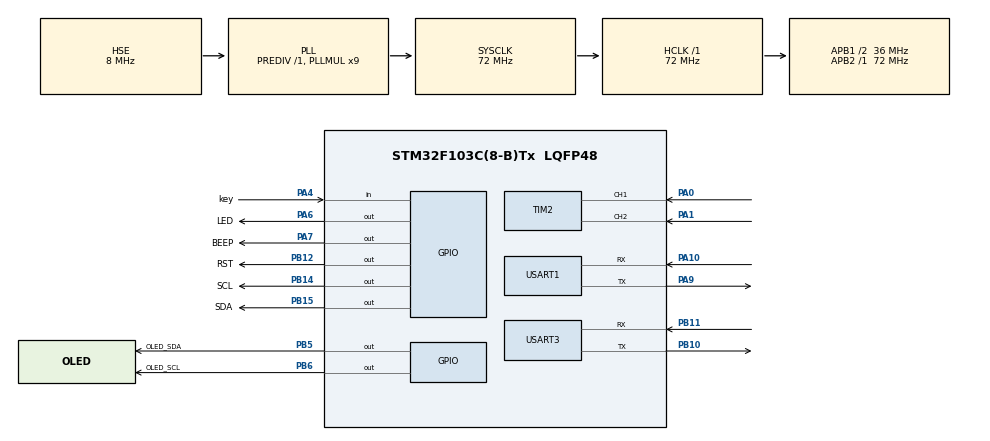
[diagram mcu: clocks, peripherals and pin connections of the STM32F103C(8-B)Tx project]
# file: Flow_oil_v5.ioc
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FREERTOS.HEAP_NUMBER=4
FREERTOS.INCLUDE_uxTaskGetStackHighWaterMark=1
FREERTOS.INCLUDE_vTaskDelay=1
FREERTOS.MEMORY_ALLOCATION=0
FREERTOS.Queues01=SendQueue,4,float,0,Dynamic,NULL,NULL;UploadQueue,1,OilDataWithTime,0,Dynamic,NULL,NULL;RequestQueue,1,uint8_t,0,Dynamic,NULL,NULL;DeleteQueue,1,uint8_t,0,Dynamic,NULL,NULL
FREERTOS.Tasks01=defaultTask,-3,64,StartDefaultTask,As weak,NULL,Dynamic,NULL,NULL;UploadDataTask,1,256,UploadData_Task,As weak,NULL,Dynamic,NULL,NULL;ProcesDataTask,0,256,ProcesData_Task,As weak,NULL,Dynamic,NULL,NULL;StorageDataTask,2,256,StorageData_Task,As weak,NULL,Dynamic,NULL,NULL;oledTask,-1,256,oled_Task,As weak,NULL,Dynamic,NULL,NULL
FREERTOS.configMINIMAL_STACK_SIZE=64
FREERTOS.configTOTAL_HEAP_SIZE=9216
IWDG.Prescaler=IWDG_PRESCALER_256
Mcu.Family=STM32F1
Mcu.Name=STM32F103C(8-B)Tx
Mcu.Package=LQFP48
NVIC.PriorityGroup=NVIC_PRIORITYGROUP_4
NVIC.TIM1_UP_IRQn=true\:15\:0\:false\:false\:true\:false\:false\:true\:true
NVIC.TimeBase=TIM1_UP_IRQn
NVIC.TimeBaseIP=TIM1
NVIC.USART3_IRQn=true\:7\:0\:true\:false\:true\:true\:true\:true\:true
PA0-WKUP.GPIO_PuPd=GPIO_PULLUP
PA0-WKUP.Signal=S_TIM2_CH1_ETR
PA1.GPIO_PuPd=GPIO_PULLUP
PA1.Signal=S_TIM2_CH2
PA10.Mode=Asynchronous
PA10.Signal=USART1_RX
PA13.Mode=Serial_Wire
PA13.Signal=SYS_JTMS-SWDIO
PA14.Mode=Serial_Wire
PA14.Signal=SYS_JTCK-SWCLK
PA4.GPIO_Label=key
PA4.GPIO_PuPd=GPIO_PULLUP
PA4.Signal=GPIO_Input
PA6.GPIO_Label=LED
PA6.GPIO_ModeDefaultOutputPP=GPIO_MODE_OUTPUT_PP
PA6.PinState=GPIO_PIN_SET
PA6.Signal=GPIO_Output
PA7.GPIO_Label=BEEP
PA7.GPIO_Speed=GPIO_SPEED_FREQ_MEDIUM
PA7.PinState=GPIO_PIN_RESET
PA7.Signal=GPIO_Output
PA9.Mode=Asynchronous
PA9.Signal=USART1_TX
PB10.Mode=Asynchronous
PB10.Signal=USART3_TX
PB11.Mode=Asynchronous
PB11.Signal=USART3_RX
PB12.GPIO_Label=RST
PB12.GPIO_ModeDefaultOutputPP=GPIO_MODE_OUTPUT_PP
PB12.GPIO_PuPd=GPIO_NOPULL
PB12.PinState=GPIO_PIN_SET
PB12.Signal=GPIO_Output
PB14.GPIO_Label=SCL
PB14.GPIO_ModeDefaultOutputPP=GPIO_MODE_OUTPUT_OD
PB14.GPIO_PuPd=GPIO_PULLUP
PB14.GPIO_Speed=GPIO_SPEED_FREQ_HIGH
PB14.PinState=GPIO_PIN_SET
PB14.Signal=GPIO_Output
PB15.GPIO_Label=SDA
PB15.GPIO_ModeDefaultOutputPP=GPIO_MODE_OUTPUT_OD
PB15.GPIO_PuPd=GPIO_PULLUP
PB15.GPIO_Speed=GPIO_SPEED_FREQ_HIGH
PB15.PinState=GPIO_PIN_SET
PB15.Signal=GPIO_Output
PB5.GPIO_Label=OLED_SDA
PB5.GPIO_ModeDefaultOutputPP=GPIO_MODE_OUTPUT_OD
PB5.GPIO_PuPd=GPIO_PULLUP
PB5.GPIO_Speed=GPIO_SPEED_FREQ_HIGH
PB5.PinState=GPIO_PIN_SET
PB5.Signal=GPIO_Output
PB6.GPIO_Label=OLED_SCL
PB6.GPIO_ModeDefaultOutputPP=GPIO_MODE_OUTPUT_OD
PB6.GPIO_PuPd=GPIO_PULLUP
PB6.GPIO_Speed=GPIO_SPEED_FREQ_HIGH
PB6.PinState=GPIO_PIN_SET
PB6.Signal=GPIO_Output
PC14-OSC32_IN.Mode=LSE-External-Oscillator
PC14-OSC32_IN.Signal=RCC_OSC32_IN
PC15-OSC32_OUT.Mode=LSE-External-Oscillator
PC15-OSC32_OUT.Signal=RCC_OSC32_OUT
PD0-OSC_IN.Mode=HSE-External-Oscillator
PD0-OSC_IN.Signal=RCC_OSC_IN
PD1-OSC_OUT.Mode=HSE-External-Oscillator
PD1-OSC_OUT.Signal=RCC_OSC_OUT
ProjectManager.HeapSize=0x400
ProjectManager.StackSize=0x1000
ProjectManager.TargetToolchain=MDK-ARM V5.32
RCC.AHBFreq_Value=72000000
RCC.APB1CLKDivider=RCC_HCLK_DIV2
RCC.APB1Freq_Value=36000000
RCC.APB1TimFreq_Value=72000000
RCC.APB2Freq_Value=72000000
RCC.APB2TimFreq_Value=72000000
RCC.HCLKFreq_Value=72000000
RCC.PLLMUL=RCC_PLL_MUL9
RCC.PLLSourceVirtual=RCC_PLLSOURCE_HSE
RCC.RTCClockSelection=RCC_RTCCLKSOURCE_LSE
RCC.SYSCLKFreq_VALUE=72000000
RCC.SYSCLKSource=RCC_SYSCLKSOURCE_PLLCLK
RCC.USBFreq_Value=72000000
SH.S_TIM2_CH1_ETR.0=TIM2_CH1,Encoder_Interface
SH.S_TIM2_CH2.0=TIM2_CH2,Encoder_Interface
TIM2.EncoderMode=TIM_ENCODERMODE_TI12
TIM2.IC1Filter=1
TIM2.IC1Polarity=TIM_ICPOLARITY_FALLING
TIM2.IC2Polarity=TIM_ICPOLARITY_FALLING
USART1.VirtualMode=VM_ASYNC
USART3.VirtualMode=VM_ASYNC
VP_FREERTOS_VS_CMSIS_V1.Mode=CMSIS_V1
VP_IWDG_VS_IWDG.Mode=IWDG_Activate
VP_RTC_VS_RTC_Activate.Mode=RTC_Enabled
VP_SYS_VS_tim1.Mode=TIM1
board=custom

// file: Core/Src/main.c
/* USER CODE BEGIN Header */
/**
  ******************************************************************************
  * @file           : main.c
  * @brief          : Main program body
  ******************************************************************************
  * @attention
  *
  * Copyright (c) 2025 STMicroelectronics.
  * All rights reserved.
  *
  * This software is licensed under terms that can be found in the LICENSE file
  * in the root directory of this software component.
  * If no LICENSE file comes with this software, it is provided AS-IS.
  *
  ******************************************************************************
  */
/* USER CODE END Header */
#include "main.h"
#include "cmsis_os.h"
#include "iwdg.h"
#include "rtc.h"
#include "tim.h"
#include "usart.h"
#include "gpio.h"

void SystemClock_Config(void);
void MX_FREERTOS_Init(void);

int main(void)
{

  /* MCU Configuration--------------------------------------------------------*/

  /* Reset of all peripherals, Initializes the Flash interface and the Systick. */
  HAL_Init();

  /* Configure the system clock */
  SystemClock_Config();

  /* Initialize all configured peripherals */
  MX_GPIO_Init();
  MX_USART1_UART_Init();
  MX_USART3_UART_Init();
  MX_RTC_Init();
  MX_IWDG_Init();
  MX_TIM2_Init();

  /* Call init function for freertos objects (in cmsis_os2.c) */
  MX_FREERTOS_Init();

  /* Start scheduler */
  osKernelStart();

  /* We should never get here as control is now taken by the scheduler */

  /* Infinite loop */
  while (1)
  {

  }
}

void SystemClock_Config(void)
{
  RCC_OscInitTypeDef RCC_OscInitStruct = {0};
  RCC_ClkInitTypeDef RCC_ClkInitStruct = {0};
  RCC_PeriphCLKInitTypeDef PeriphClkInit = {0};

  /** Initializes the RCC Oscillators according to the specified parameters
  * in the RCC_OscInitTypeDef structure.
  */
  RCC_OscInitStruct.OscillatorType = RCC_OSCILLATORTYPE_LSI|RCC_OSCILLATORTYPE_HSE
                              |RCC_OSCILLATORTYPE_LSE;
  RCC_OscInitStruct.HSEState = RCC_HSE_ON;
  RCC_OscInitStruct.HSEPredivValue = RCC_HSE_PREDIV_DIV1;
  RCC_OscInitStruct.LSEState = RCC_LSE_ON;
  RCC_OscInitStruct.HSIState = RCC_HSI_ON;
  RCC_OscInitStruct.LSIState = RCC_LSI_ON;
  RCC_OscInitStruct.PLL.PLLState = RCC_PLL_ON;
  RCC_OscInitStruct.PLL.PLLSource = RCC_PLLSOURCE_HSE;
  RCC_OscInitStruct.PLL.PLLMUL = RCC_PLL_MUL9;
  if (HAL_RCC_OscConfig(&RCC_OscInitStruct) != HAL_OK)
  {
    Error_Handler();
  }

  /** Initializes the CPU, AHB and APB buses clocks
  */
  RCC_ClkInitStruct.ClockType = RCC_CLOCKTYPE_HCLK|RCC_CLOCKTYPE_SYSCLK
                              |RCC_CLOCKTYPE_PCLK1|RCC_CLOCKTYPE_PCLK2;
  RCC_ClkInitStruct.SYSCLKSource = RCC_SYSCLKSOURCE_PLLCLK;
  RCC_ClkInitStruct.AHBCLKDivider = RCC_SYSCLK_DIV1;
  RCC_ClkInitStruct.APB1CLKDivider = RCC_HCLK_DIV2;
  RCC_ClkInitStruct.APB2CLKDivider = RCC_HCLK_DIV1;

  if (HAL_RCC_ClockConfig(&RCC_ClkInitStruct, FLASH_LATENCY_2) != HAL_OK)
  {
    Error_Handler();
  }
  PeriphClkInit.PeriphClockSelection = RCC_PERIPHCLK_RTC;
  PeriphClkInit.RTCClockSelection = RCC_RTCCLKSOURCE_LSE;
  if (HAL_RCCEx_PeriphCLKConfig(&PeriphClkInit) != HAL_OK)
  {
    Error_Handler();
  }
}

void HAL_TIM_PeriodElapsedCallback(TIM_HandleTypeDef *htim)
{
  if (htim->Instance == TIM1)
  {
    HAL_IncTick();
  }
}

void Error_Handler(void)
{
  __disable_irq();
  while (1)
  {
  }
}

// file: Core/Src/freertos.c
/* USER CODE BEGIN Header */
/**
  ******************************************************************************
  * File Name          : freertos.c
  * Description        : Code for freertos applications
  ******************************************************************************
  * @attention
  *
  * Copyright (c) 2025 STMicroelectronics.
  * All rights reserved.
  *
  * This software is licensed under terms that can be found in the LICENSE file
  * in the root directory of this software component.
  * If no LICENSE file comes with this software, it is provided AS-IS.
  *
  ******************************************************************************
  */
/* USER CODE END Header */

#include "FreeRTOS.h"
#include "task.h"
#include "main.h"
#include "cmsis_os.h"

/* USER CODE BEGIN Includes */
#include "eeprom_drive.h"
#include "stdio.h"
#include "led.h"
#include "iwdg.h"
/* USER CODE END Includes */

osThreadId defaultTaskHandle;
osThreadId UploadDataTaskHandle;
osThreadId ProcesDataTaskHandle;
osThreadId StorageDataTaskHandle;
osThreadId oledTaskHandle;
osMessageQId SendQueueHandle;
osMessageQId UploadQueueHandle;
osMessageQId RequestQueueHandle;
osMessageQId DeleteQueueHandle;

void StartDefaultTask(void const * argument);
void UploadData_Task(void const * argument);
void ProcesData_Task(void const * argument);
void StorageData_Task(void const * argument);
void oled_Task(void const * argument);

void MX_FREERTOS_Init(void); /* (MISRA C 2004 rule 8.1) */

void MX_FREERTOS_Init(void) {

  /* Create the queue(s) */
  /* definition and creation of SendQueue */
  osMessageQDef(SendQueue, 4, float);
  SendQueueHandle = osMessageCreate(osMessageQ(SendQueue), NULL);

  /* definition and creation of UploadQueue */
  osMessageQDef(UploadQueue, 1, OilDataWithTime);
  UploadQueueHandle = osMessageCreate(osMessageQ(UploadQueue), NULL);

  /* definition and creation of RequestQueue */
  osMessageQDef(RequestQueue, 1, uint8_t);
  RequestQueueHandle = osMessageCreate(osMessageQ(RequestQueue), NULL);

  /* definition and creation of DeleteQueue */
  osMessageQDef(DeleteQueue, 1, uint8_t);
  DeleteQueueHandle = osMessageCreate(osMessageQ(DeleteQueue), NULL);

  /* Create the thread(s) */
  /* definition and creation of defaultTask */
  osThreadDef(defaultTask, StartDefaultTask, osPriorityIdle, 0, 64);
  defaultTaskHandle = osThreadCreate(osThread(defaultTask), NULL);

  /* definition and creation of UploadDataTask */
  osThreadDef(UploadDataTask, UploadData_Task, osPriorityAboveNormal, 0, 256);
  UploadDataTaskHandle = osThreadCreate(osThread(UploadDataTask), NULL);

  /* definition and creation of ProcesDataTask */
  osThreadDef(ProcesDataTask, ProcesData_Task, osPriorityNormal, 0, 256);
  ProcesDataTaskHandle = osThreadCreate(osThread(ProcesDataTask), NULL);

  /* definition and creation of StorageDataTask */
  osThreadDef(StorageDataTask, StorageData_Task, osPriorityHigh, 0, 256);
  StorageDataTaskHandle = osThreadCreate(osThread(StorageDataTask), NULL);

  /* definition and creation of oledTask */
  osThreadDef(oledTask, oled_Task, osPriorityBelowNormal, 0, 256);
  oledTaskHandle = osThreadCreate(osThread(oledTask), NULL);

}

__weak void StartDefaultTask(void const * argument)
{
  /* USER CODE BEGIN StartDefaultTask */
  HAL_IWDG_Init(&hiwdg);
  /* Infinite loop */
  for(;;)
  {
    vTaskDelay(4000);
    HAL_IWDG_Refresh(&hiwdg); // ι��
  }
  /* USER CODE END StartDefaultTask */
}

__weak void UploadData_Task(void const * argument)
{
  for(;;)
  {
    osDelay(1);
  }
}

__weak void ProcesData_Task(void const * argument)
{
  for(;;)
  {
    osDelay(1);
  }
}

__weak void StorageData_Task(void const * argument)
{
  for(;;)
  {
    osDelay(1);
  }
}

__weak void oled_Task(void const * argument)
{
  for(;;)
  {
    osDelay(1);
  }
}
